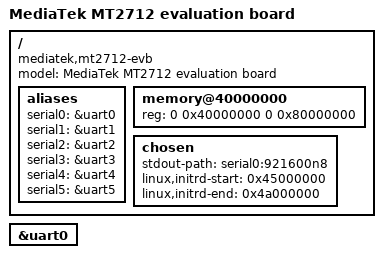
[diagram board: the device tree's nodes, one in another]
/*
 * Copyright (c) 2017 MediaTek Inc.
 * Author: YT Shen <yt.shen@mediatek.com>
 *
 * SPDX-License-Identifier: (GPL-2.0 OR MIT)
 */

/dts-v1/;
#include "mt2712e.dtsi"

/ {
	model = "MediaTek MT2712 evaluation board";
	compatible = "mediatek,mt2712-evb", "mediatek,mt2712";

	aliases {
		serial0 = &uart0;
		serial1 = &uart1;
		serial2 = &uart2;
		serial3 = &uart3;
		serial4 = &uart4;
		serial5 = &uart5;
	};

	memory@40000000 {
		device_type = "memory";
		reg = <0 0x40000000 0 0x80000000>;
	};

	chosen {
		stdout-path = "serial0:921600n8";
		linux,initrd-start = <0x45000000>;
		linux,initrd-end   = <0x4a000000>;
	};
};

&uart0 {
	status = "okay";
};

